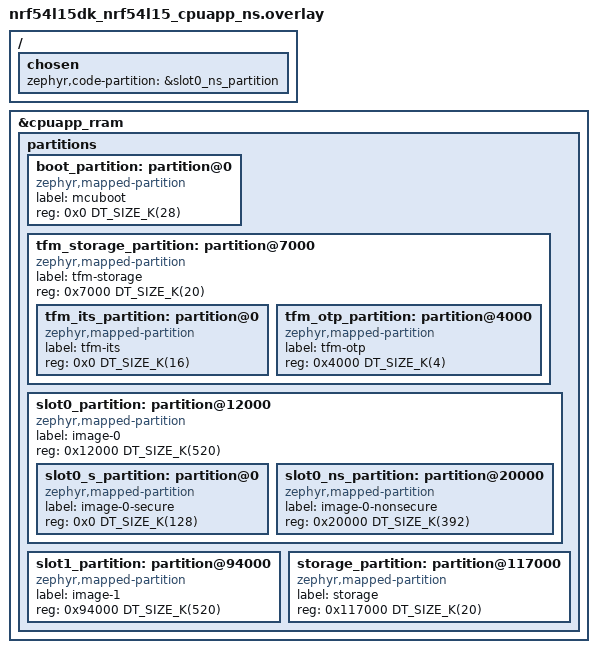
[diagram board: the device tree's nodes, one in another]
/*
 * Copyright (c) 2026 Nordic Semiconductor ASA
 *
 * SPDX-License-Identifier: LicenseRef-Nordic-5-Clause
 */

/ {
	chosen {
		zephyr,code-partition = &slot0_ns_partition;
	};
};

&cpuapp_rram {
	/delete-node/ partitions;

	partitions {
		ranges;
		#address-cells = <1>;
		#size-cells = <1>;

		boot_partition: partition@0 {
			compatible = "zephyr,mapped-partition";
			label = "mcuboot";
			reg = <0x0 DT_SIZE_K(28)>;
		};

		tfm_storage_partition: partition@7000 {
			compatible = "zephyr,mapped-partition";
			label = "tfm-storage";
			reg = <0x7000 DT_SIZE_K(20)>;
			ranges = <0x0 0x7000 DT_SIZE_K(20)>;
			#address-cells = <1>;
			#size-cells = <1>;

			tfm_its_partition: partition@0 {
				compatible = "zephyr,mapped-partition";
				label = "tfm-its";
				reg = <0x0 DT_SIZE_K(16)>;
			};

			tfm_otp_partition: partition@4000 {
				compatible = "zephyr,mapped-partition";
				label = "tfm-otp";
				reg = <0x4000 DT_SIZE_K(4)>;
			};
		};

		slot0_partition: partition@12000 {
			compatible = "zephyr,mapped-partition";
			label = "image-0";
			reg = <0x12000 DT_SIZE_K(520)>;
			ranges = <0x0 0x12000 DT_SIZE_K(520)>;
			#address-cells = <1>;
			#size-cells = <1>;

			slot0_s_partition: partition@0 {
				compatible = "zephyr,mapped-partition";
				label = "image-0-secure";
				reg = <0x0 DT_SIZE_K(128)>;
			};

			slot0_ns_partition: partition@20000 {
				compatible = "zephyr,mapped-partition";
				label = "image-0-nonsecure";
				reg = <0x20000 DT_SIZE_K(392)>;
			};
		};

		slot1_partition: partition@94000 {
			compatible = "zephyr,mapped-partition";
			label = "image-1";
			reg = <0x94000 DT_SIZE_K(520)>;
		};

		storage_partition: partition@117000 {
			compatible = "zephyr,mapped-partition";
			label = "storage";
			reg = <0x117000 DT_SIZE_K(20)>;
		};
	};
};
